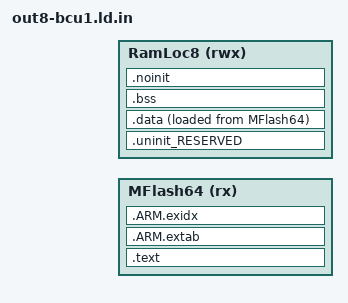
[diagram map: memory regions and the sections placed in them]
/*
 * Linker script for out8-bcu1 (LPC1115/303), generated by CMake from out8-bcu1.ld.in
 *
 * Based on the MCUXpresso managed linker script (Code Red/NXP, BSD-3-Clause)
 * as used in misc/ft12, with the memory layout of linkscripts/memory.ldt:
 *   - standalone:          flash  0x0    / 60 KB (last 4 KB sector = UserEeprom), RAM 0x10000000 / 8 KB
 *   - "Flashstart 0xWXYZ":  flash  0xWXYZ / 60 KB - 0xWXYZ,
 *                          RAM    0x100000d4 / 8 KB - 0xd4 (bus updater copies 0xd4 bytes)
 *
 * Start-up code: src/startup_lpc11xx.cpp (symbols __data_load__, __data_start__, __bss_start__ ...),
 * heap and abort(): src/libc_stubs.cpp (no NXP run-time library)
 *
 * Copyright (c) 2026 Doumanix <doumanix@gmx.de>
 *
 * Variant: @OUT8_LD_VARIANT@
 */

GROUP (
  "libgcc.a"
  "libc_nano.a"
  "libstdc++_nano.a"
  "libm.a"
  "crti.o"
  "crtn.o"
  "crtbegin.o"
  "crtend.o"
)
MEMORY
{
    /* Define each memory region */
    MFlash64 (rx) : ORIGIN = @OUT8_FLASH_ORIGIN@, LENGTH = @OUT8_FLASH_LENGTH@
    RamLoc8 (rwx) : ORIGIN = @OUT8_RAM_ORIGIN@, LENGTH = @OUT8_RAM_LENGTH@
}

      /* Define a symbol for the top of each memory region */
      __base_MFlash64 = @OUT8_FLASH_ORIGIN@; /* MFlash64 */
      __base_Flash = @OUT8_FLASH_ORIGIN@; /* Flash */
      __top_MFlash64 = @OUT8_FLASH_ORIGIN@ + @OUT8_FLASH_LENGTH@;
      __top_Flash = @OUT8_FLASH_ORIGIN@ + @OUT8_FLASH_LENGTH@;
      __base_RamLoc8 = @OUT8_RAM_ORIGIN@; /* RamLoc8 */
      __base_RAM = @OUT8_RAM_ORIGIN@; /* RAM */
      __top_RamLoc8 = @OUT8_RAM_ORIGIN@ + @OUT8_RAM_LENGTH@;
      __top_RAM = @OUT8_RAM_ORIGIN@ + @OUT8_RAM_LENGTH@;

ENTRY(Reset_Handler)

SECTIONS
{
     /* MAIN TEXT SECTION */
    .text : ALIGN(4)
    {
        FILL(0xff)
        __vectors_start__ = ABSOLUTE(.) ;
        KEEP(*(.isr_vector))
        . = ALIGN(4) ;

       *(.text*)
       *(.rodata .rodata.* .constdata .constdata.*)
       . = ALIGN(4);
            /* C++ constructors etc */
            . = ALIGN(4);
            KEEP(*(.init))

            . = ALIGN(4);
            __preinit_array_start = .;
            KEEP (*(.preinit_array))
            __preinit_array_end = .;

            . = ALIGN(4);
            __init_array_start = .;
            KEEP (*(SORT(.init_array.*)))
            KEEP (*(.init_array))
            __init_array_end = .;

            KEEP(*(.fini));

            . = ALIGN(4);
            KEEP (*crtbegin.o(.ctors))
            KEEP (*(EXCLUDE_FILE (*crtend.o) .ctors))
            KEEP (*(SORT(.ctors.*)))
            KEEP (*crtend.o(.ctors))

            . = ALIGN(4);
            KEEP (*crtbegin.o(.dtors))
            KEEP (*(EXCLUDE_FILE (*crtend.o) .dtors))
            KEEP (*(SORT(.dtors.*)))
            KEEP (*crtend.o(.dtors))
            . = ALIGN(4);
            /* End C++ */
    } > MFlash64
    /*
     * for exception handling/unwind - some Newlib functions (in common
     * with C++ and STDC++) use this.
     */
    .ARM.extab : ALIGN(4)
    {
        *(.ARM.extab* .gnu.linkonce.armextab.*)
    } > MFlash64

    .ARM.exidx : ALIGN(4)
    {
        __exidx_start = .;
        *(.ARM.exidx* .gnu.linkonce.armexidx.*)
        __exidx_end = .;
    } > MFlash64

    _etext = .;
    __etext = .;

    /* MAIN DATA SECTION */
    .uninit_RESERVED (NOLOAD) : ALIGN(4)
    {
        _start_uninit_RESERVED = .;
        KEEP(*(.bss.$RESERVED*))
       . = ALIGN(4) ;
        _end_uninit_RESERVED = .;
    } > RamLoc8 AT> RamLoc8

    /* Main DATA section (RamLoc8) */
    .data : ALIGN(4)
    {
       FILL(0xff)
       _data = . ;
       __data_start__ = . ;
       PROVIDE(__start_data_RAM = .) ;
       PROVIDE(__start_data_RamLoc8 = .) ;
       *(vtable)
       *(.ramfunc*)
       KEEP(*(CodeQuickAccess))
       KEEP(*(DataQuickAccess))
       *(RamFunction)
       *(.data*)
       . = ALIGN(4) ;
       _edata = . ;
       __data_end__ = . ;
       PROVIDE(__end_data_RAM = .) ;
       PROVIDE(__end_data_RamLoc8 = .) ;
    } > RamLoc8 AT>MFlash64
    __data_load__ = LOADADDR(.data);

    /* MAIN BSS SECTION */
    .bss (NOLOAD) : ALIGN(4)
    {
        _bss = .;
        __bss_start__ = .;
        PROVIDE(__start_bss_RAM = .) ;
        PROVIDE(__start_bss_RamLoc8 = .) ;
        *(.bss*)
        *(COMMON)
        . = ALIGN(4) ;
        _ebss = .;
        __bss_end__ = .;
        PROVIDE(__end_bss_RAM = .) ;
        PROVIDE(__end_bss_RamLoc8 = .) ;
        PROVIDE(end = .);
    } > RamLoc8 AT> RamLoc8

    /* DEFAULT NOINIT SECTION */
    .noinit (NOLOAD): ALIGN(4)
    {
        _noinit = .;
        PROVIDE(__start_noinit_RAM = .) ;
        PROVIDE(__start_noinit_RamLoc8 = .) ;
        *(.noinit*)
         . = ALIGN(4) ;
        _end_noinit = .;
       PROVIDE(__end_noinit_RAM = .) ;
       PROVIDE(__end_noinit_RamLoc8 = .) ;
    } > RamLoc8 AT> RamLoc8

    /* Heap from here up to the stack (_sbrk), stack from the top of RAM downwards */
    __HeapBase = .;
    __StackTop = __top_RamLoc8;

    /* Checksum of the vectors 0..6 for the LPC boot ROM, stored in vector 7 by the start-up code */
    __valid_user_code_checksum = 0 - (__StackTop
                                      + (Reset_Handler + 1)
                                      + (NMI_Handler + 1)
                                      + (HardFault_Handler + 1));

    /* Provide basic symbols giving location and size of main text
     * block, including initial values of RW data sections. Note that
     * these will need extending to give a complete picture with
     * complex images (e.g multiple Flash banks).
     */
    _image_start = LOADADDR(.text);
    _image_end = LOADADDR(.data) + SIZEOF(.data);
    _image_size = _image_end - _image_start;
}
